# M55M1 register map
File version: 1.0
Registers are 32-bit, read-write, reset 0x0 unless marked. A register's access mark holds for its fields unless they carry their own. Offsets are from the block's base; [hi:lo] are bit positions; {n}, {i} and the like mark numbered series; 'fields as' and 'values as' point back to an identical list.

## SYS (part 3 of 3) — SYS Register Map
Base 0x40000000
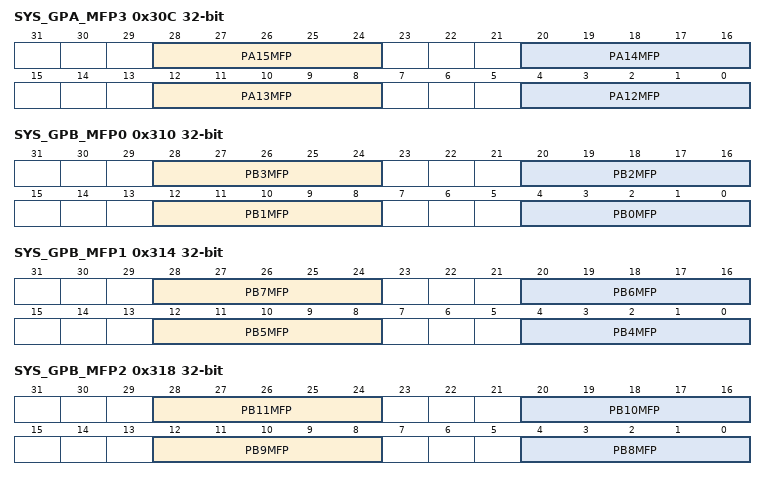
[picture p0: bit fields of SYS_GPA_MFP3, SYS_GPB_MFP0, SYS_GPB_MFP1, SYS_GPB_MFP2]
0x30C SYS_GPA_MFP3 — GPIOA Multiple Function Control Register 3
  [28:24] PA15MFP — PA.15 Multi-function Pin Selection. Note: These bits are not retained when D2 power is turned off.
  [20:16] PA14MFP — PA.14 Multi-function Pin Selection. Note: These bits are not retained when D2 power is turned off.
  [12:8] PA13MFP — PA.13 Multi-function Pin Selection. Note: These bits are not retained when D2 power is turned off.
  [4:0] PA12MFP — PA.12 Multi-function Pin Selection. Note: These bits are not retained when D2 power is turned off.
0x310 SYS_GPB_MFP0 — GPIOB Multiple Function Control Register 0
  [28:24] PB3MFP — PB.3 Multi-function Pin Selection. Note: These bits are not retained when D2 power is turned off.
  [20:16] PB2MFP — PB.2 Multi-function Pin Selection. Note: These bits are not retained when D2 power is turned off.
  [12:8] PB1MFP — PB.1 Multi-function Pin Selection. Note: These bits are not retained when D2 power is turned off.
  [4:0] PB0MFP — PB.0 Multi-function Pin Selection. Note: These bits are not retained when D2 power is turned off.
0x314 SYS_GPB_MFP1 — GPIOB Multiple Function Control Register 1
  [28:24] PB7MFP — PB.7 Multi-function Pin Selection. Note: These bits are not retained when D2 power is turned off.
  [20:16] PB6MFP — PB.6 Multi-function Pin Selection. Note: These bits are not retained when D2 power is turned off.
  [12:8] PB5MFP — PB.5 Multi-function Pin Selection. Note: These bits are not retained when D2 power is turned off.
  [4:0] PB4MFP — PB.4 Multi-function Pin Selection. Note: These bits are not retained when D2 power is turned off.
0x318 SYS_GPB_MFP2 — GPIOB Multiple Function Control Register 2
  [28:24] PB11MFP — PB.11 Multi-function Pin Selection. Note: These bits are not retained when D2 power is turned off.
  [20:16] PB10MFP — PB.10 Multi-function Pin Selection. Note: These bits are not retained when D2 power is turned off.
  [12:8] PB9MFP — PB.9 Multi-function Pin Selection. Note: These bits are not retained when D2 power is turned off.
  [4:0] PB8MFP — PB.8 Multi-function Pin Selection. Note: These bits are not retained when D2 power is turned off.
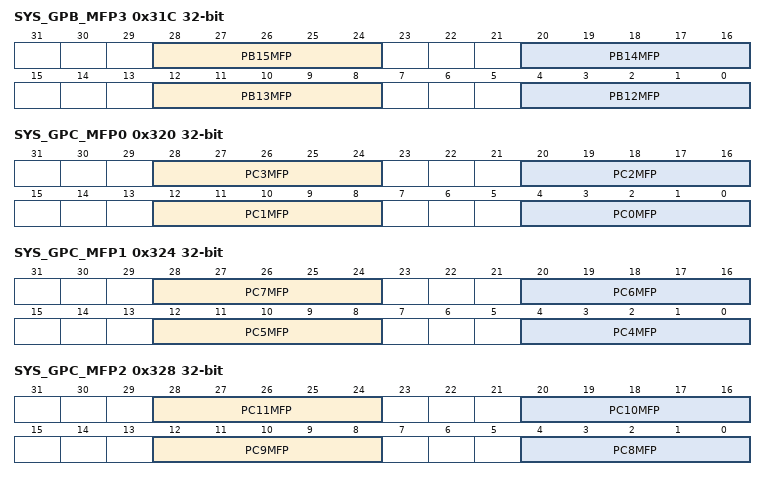
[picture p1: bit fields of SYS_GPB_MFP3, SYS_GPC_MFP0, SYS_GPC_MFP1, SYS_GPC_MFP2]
0x31C SYS_GPB_MFP3 — GPIOB Multiple Function Control Register 3
  [28:24] PB15MFP — PB.15 Multi-function Pin Selection. Note: These bits are not retained when D2 power is turned off.
  [20:16] PB14MFP — PB.14 Multi-function Pin Selection. Note: These bits are not retained when D2 power is turned off.
  [12:8] PB13MFP — PB.13 Multi-function Pin Selection. Note: These bits are not retained when D2 power is turned off.
  [4:0] PB12MFP — PB.12 Multi-function Pin Selection. Note: These bits are not retained when D2 power is turned off.
0x320 SYS_GPC_MFP0 — GPIOC Multiple Function Control Register 0
  [28:24] PC3MFP — PC.3 Multi-function Pin Selection. Note: These bits are not retained when D2 power is turned off.
  [20:16] PC2MFP — PC.2 Multi-function Pin Selection. Note: These bits are not retained when D2 power is turned off.
  [12:8] PC1MFP — PC.1 Multi-function Pin Selection. Note: These bits are not retained when D2 power is turned off.
  [4:0] PC0MFP — PC.0 Multi-function Pin Selection. Note: These bits are not retained when D2 power is turned off.
0x324 SYS_GPC_MFP1 — GPIOC Multiple Function Control Register 1
  [28:24] PC7MFP — PC.7 Multi-function Pin Selection. Note: These bits are not retained when D2 power is turned off.
  [20:16] PC6MFP — PC.6 Multi-function Pin Selection. Note: These bits are not retained when D2 power is turned off.
  [12:8] PC5MFP — PC.5 Multi-function Pin Selection. Note: These bits are not retained when D2 power is turned off.
  [4:0] PC4MFP — PC.4 Multi-function Pin Selection. Note: These bits are not retained when D2 power is turned off.
0x328 SYS_GPC_MFP2 — GPIOC Multiple Function Control Register 2
  [28:24] PC11MFP — PC.11 Multi-function Pin Selection. Note: These bits are not retained when D2 power is turned off.
  [20:16] PC10MFP — PC.10 Multi-function Pin Selection. Note: These bits are not retained when D2 power is turned off.
  [12:8] PC9MFP — PC.9 Multi-function Pin Selection. Note: These bits are not retained when D2 power is turned off.
  [4:0] PC8MFP — PC.8 Multi-function Pin Selection. Note: These bits are not retained when D2 power is turned off.
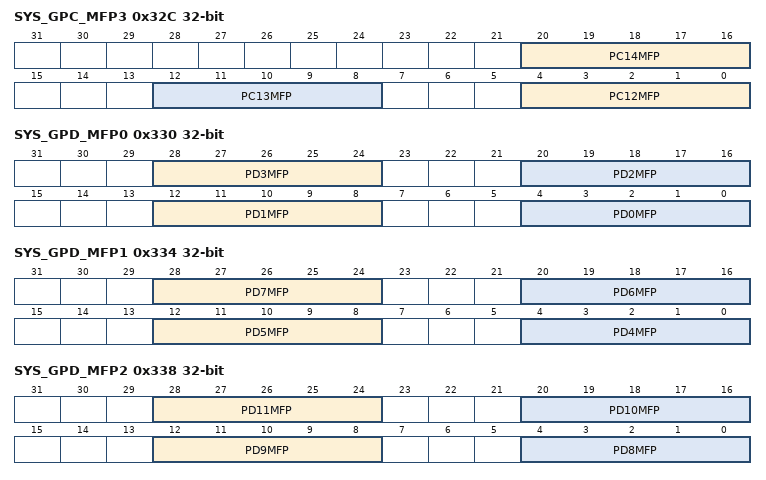
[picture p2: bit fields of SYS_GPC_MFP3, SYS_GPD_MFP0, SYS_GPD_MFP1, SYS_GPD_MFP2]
0x32C SYS_GPC_MFP3 — GPIOC Multiple Function Control Register 3
  [20:16] PC14MFP — PC.14 Multi-function Pin Selection. Note: These bits are not retained when D2 power is turned off.
  [12:8] PC13MFP — PC.13 Multi-function Pin Selection. Note: These bits are not retained when D2 power is turned off.
  [4:0] PC12MFP — PC.12 Multi-function Pin Selection. Note: These bits are not retained when D2 power is turned off.
0x330 SYS_GPD_MFP0 — GPIOD Multiple Function Control Register 0
  [28:24] PD3MFP — PD.3 Multi-function Pin Selection. Note: These bits are not retained when D2 power is turned off.
  [20:16] PD2MFP — PD.2 Multi-function Pin Selection. Note: These bits are not retained when D2 power is turned off.
  [12:8] PD1MFP — PD.1 Multi-function Pin Selection. Note: These bits are not retained when D2 power is turned off.
  [4:0] PD0MFP — PD.0 Multi-function Pin Selection. Note: These bits are not retained when D2 power is turned off.
0x334 SYS_GPD_MFP1 — GPIOD Multiple Function Control Register 1
  [28:24] PD7MFP — PD.7 Multi-function Pin Selection. Note: These bits are not retained when D2 power is turned off.
  [20:16] PD6MFP — PD.6 Multi-function Pin Selection. Note: These bits are not retained when D2 power is turned off.
  [12:8] PD5MFP — PD.5 Multi-function Pin Selection. Note: These bits are not retained when D2 power is turned off.
  [4:0] PD4MFP — PD.4 Multi-function Pin Selection. Note: These bits are not retained when D2 power is turned off.
0x338 SYS_GPD_MFP2 — GPIOD Multiple Function Control Register 2
  [28:24] PD11MFP — PD.11 Multi-function Pin Selection. Note: These bits are not retained when D2 power is turned off.
  [20:16] PD10MFP — PD.10 Multi-function Pin Selection. Note: These bits are not retained when D2 power is turned off.
  [12:8] PD9MFP — PD.9 Multi-function Pin Selection. Note: These bits are not retained when D2 power is turned off.
  [4:0] PD8MFP — PD.8 Multi-function Pin Selection. Note: These bits are not retained when D2 power is turned off.
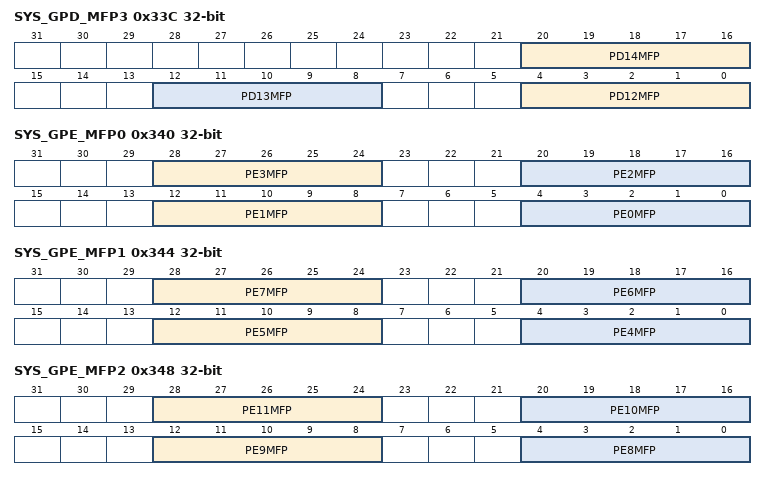
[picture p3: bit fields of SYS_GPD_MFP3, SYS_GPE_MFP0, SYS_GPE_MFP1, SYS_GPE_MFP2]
0x33C SYS_GPD_MFP3 — GPIOD Multiple Function Control Register 3
  [20:16] PD14MFP — PD.14 Multi-function Pin Selection. Note: These bits are not retained when D2 power is turned off.
  [12:8] PD13MFP — PD.13 Multi-function Pin Selection. Note: These bits are not retained when D2 power is turned off.
  [4:0] PD12MFP — PD.12 Multi-function Pin Selection. Note: These bits are not retained when D2 power is turned off.
0x340 SYS_GPE_MFP0 — GPIOE Multiple Function Control Register 0
  [28:24] PE3MFP — PE.3 Multi-function Pin Selection. Note: These bits are not retained when D2 power is turned off.
  [20:16] PE2MFP — PE.2 Multi-function Pin Selection. Note: These bits are not retained when D2 power is turned off.
  [12:8] PE1MFP — PE.1 Multi-function Pin Selection. Note: These bits are not retained when D2 power is turned off.
  [4:0] PE0MFP — PE.0 Multi-function Pin Selection. Note: These bits are not retained when D2 power is turned off.
0x344 SYS_GPE_MFP1 — GPIOE Multiple Function Control Register 1
  [28:24] PE7MFP — PE.7 Multi-function Pin Selection. Note: These bits are not retained when D2 power is turned off.
  [20:16] PE6MFP — PE.6 Multi-function Pin Selection. Note: These bits are not retained when D2 power is turned off.
  [12:8] PE5MFP — PE.5 Multi-function Pin Selection. Note: These bits are not retained when D2 power is turned off.
  [4:0] PE4MFP — PE.4 Multi-function Pin Selection. Note: These bits are not retained when D2 power is turned off.
0x348 SYS_GPE_MFP2 — GPIOE Multiple Function Control Register 2
  [28:24] PE11MFP — PE.11 Multi-function Pin Selection. Note: These bits are not retained when D2 power is turned off.
  [20:16] PE10MFP — PE.10 Multi-function Pin Selection. Note: These bits are not retained when D2 power is turned off.
  [12:8] PE9MFP — PE.9 Multi-function Pin Selection. Note: These bits are not retained when D2 power is turned off.
  [4:0] PE8MFP — PE.8 Multi-function Pin Selection. Note: These bits are not retained when D2 power is turned off.
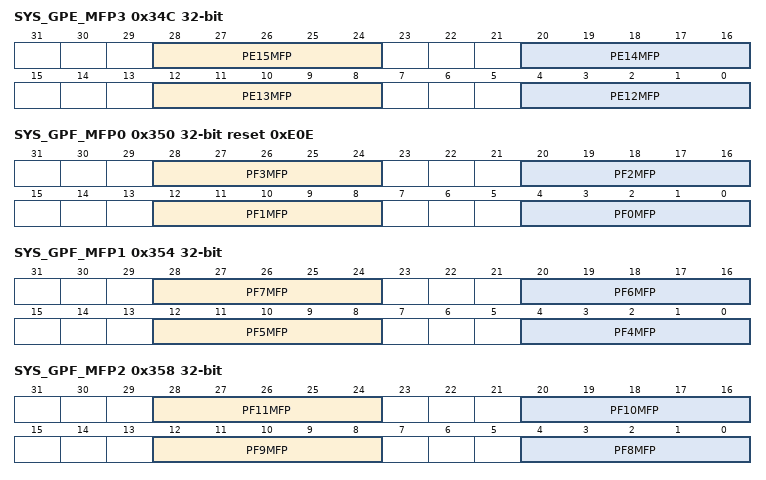
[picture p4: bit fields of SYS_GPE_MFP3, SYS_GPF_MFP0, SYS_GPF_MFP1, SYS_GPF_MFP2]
0x34C SYS_GPE_MFP3 — GPIOE Multiple Function Control Register 3
  [28:24] PE15MFP — PE.15 Multi-function Pin Selection. Note: These bits are not retained when D2 power is turned off.
  [20:16] PE14MFP — PE.14 Multi-function Pin Selection. Note: These bits are not retained when D2 power is turned off.
  [12:8] PE13MFP — PE.13 Multi-function Pin Selection. Note: These bits are not retained when D2 power is turned off.
  [4:0] PE12MFP — PE.12 Multi-function Pin Selection. Note: These bits are not retained when D2 power is turned off.
0x350 SYS_GPF_MFP0 reset 0xE0E — GPIOF Multiple Function Control Register 0
  [28:24] PF3MFP — PF.3 Multi-function Pin Selection. Note: These bits are not retained when D2 power is turned off.
  [20:16] PF2MFP — PF.2 Multi-function Pin Selection. Note: These bits are not retained when D2 power is turned off.
  [12:8] PF1MFP — PF.1 Multi-function Pin Selection. Note: These bits are not retained when D2 power is turned off.
  [4:0] PF0MFP — PF.0 Multi-function Pin Selection. Note: These bits are not retained when D2 power is turned off.
0x354 SYS_GPF_MFP1 — GPIOF Multiple Function Control Register 1
  [28:24] PF7MFP — PF.7 Multi-function Pin Selection. Note: These bits are not retained when D2 power is turned off.
  [20:16] PF6MFP — PF.6 Multi-function Pin Selection. Note: These bits are not retained when D2 power is turned off.
  [12:8] PF5MFP — PF.5 Multi-function Pin Selection. Note: These bits are not retained when D2 power is turned off.
  [4:0] PF4MFP — PF.4 Multi-function Pin Selection. Note: These bits are not retained when D2 power is turned off.
0x358 SYS_GPF_MFP2 — GPIOF Multiple Function Control Register 2
  [28:24] PF11MFP — PF.11 Multi-function Pin Selection. Note: These bits are not retained when D2 power is turned off.
  [20:16] PF10MFP — PF.10 Multi-function Pin Selection. Note: These bits are not retained when D2 power is turned off.
  [12:8] PF9MFP — PF.9 Multi-function Pin Selection. Note: These bits are not retained when D2 power is turned off.
  [4:0] PF8MFP — PF.8 Multi-function Pin Selection. Note: These bits are not retained when D2 power is turned off.
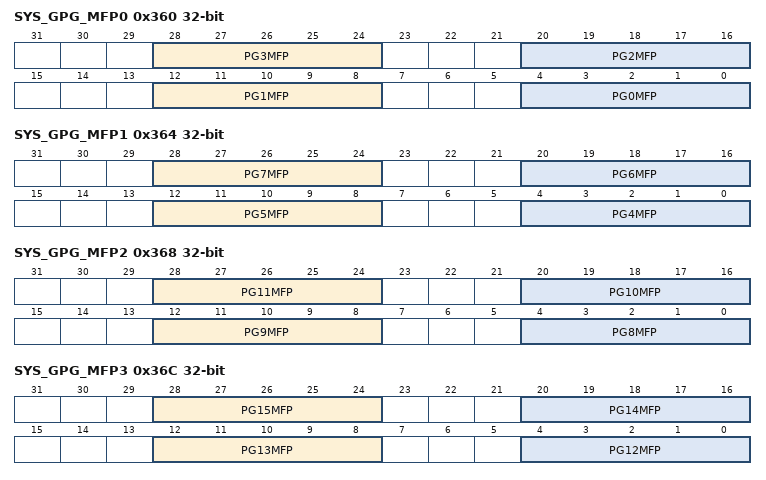
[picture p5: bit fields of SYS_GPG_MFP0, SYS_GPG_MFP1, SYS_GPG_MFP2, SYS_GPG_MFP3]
0x360 SYS_GPG_MFP0 — GPIOG Multiple Function Control Register 0
  [28:24] PG3MFP — PG.3 Multi-function Pin Selection. Note: These bits are not retained when D2 power is turned off.
  [20:16] PG2MFP — PG.2 Multi-function Pin Selection. Note: These bits are not retained when D2 power is turned off.
  [12:8] PG1MFP — PG.1 Multi-function Pin Selection. Note: These bits are not retained when D2 power is turned off.
  [4:0] PG0MFP — PG.0 Multi-function Pin Selection. Note: These bits are not retained when D2 power is turned off.
0x364 SYS_GPG_MFP1 — GPIOG Multiple Function Control Register 1
  [28:24] PG7MFP — PG.7 Multi-function Pin Selection. Note: These bits are not retained when D2 power is turned off.
  [20:16] PG6MFP — PG.6 Multi-function Pin Selection. Note: These bits are not retained when D2 power is turned off.
  [12:8] PG5MFP — PG.5 Multi-function Pin Selection. Note: These bits are not retained when D2 power is turned off.
  [4:0] PG4MFP — PG.4 Multi-function Pin Selection. Note: These bits are not retained when D2 power is turned off.
0x368 SYS_GPG_MFP2 — GPIOG Multiple Function Control Register 2
  [28:24] PG11MFP — PG.11 Multi-function Pin Selection. Note: These bits are not retained when D2 power is turned off.
  [20:16] PG10MFP — PG.10 Multi-function Pin Selection. Note: These bits are not retained when D2 power is turned off.
  [12:8] PG9MFP — PG.9 Multi-function Pin Selection. Note: These bits are not retained when D2 power is turned off.
  [4:0] PG8MFP — PG.8 Multi-function Pin Selection. Note: These bits are not retained when D2 power is turned off.
0x36C SYS_GPG_MFP3 — GPIOG Multiple Function Control Register 3
  [28:24] PG15MFP — PG.15 Multi-function Pin Selection. Note: These bits are not retained when D2 power is turned off.
  [20:16] PG14MFP — PG.14 Multi-function Pin Selection. Note: These bits are not retained when D2 power is turned off.
  [12:8] PG13MFP — PG.13 Multi-function Pin Selection. Note: These bits are not retained when D2 power is turned off.
  [4:0] PG12MFP — PG.12 Multi-function Pin Selection. Note: These bits are not retained when D2 power is turned off.
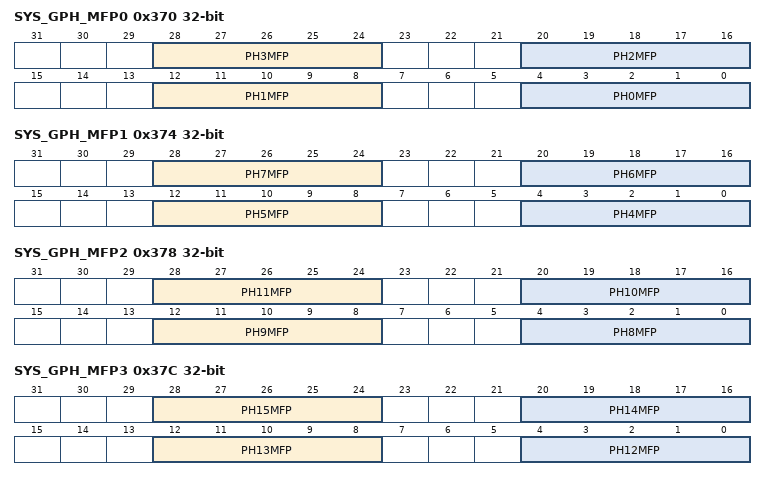
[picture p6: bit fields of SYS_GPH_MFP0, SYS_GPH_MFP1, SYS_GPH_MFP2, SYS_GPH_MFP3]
0x370 SYS_GPH_MFP0 — GPIOH Multiple Function Control Register 0
  [28:24] PH3MFP — PH.3 Multi-function Pin Selection. Note: These bits are not retained when D2 power is turned off.
  [20:16] PH2MFP — PH.2 Multi-function Pin Selection. Note: These bits are not retained when D2 power is turned off.
  [12:8] PH1MFP — PH.1 Multi-function Pin Selection. Note: These bits are not retained when D2 power is turned off.
  [4:0] PH0MFP — PH.0 Multi-function Pin Selection. Note: These bits are not retained when D2 power is turned off.
0x374 SYS_GPH_MFP1 — GPIOH Multiple Function Control Register 1
  [28:24] PH7MFP — PH.7 Multi-function Pin Selection. Note: These bits are not retained when D2 power is turned off.
  [20:16] PH6MFP — PH.6 Multi-function Pin Selection. Note: These bits are not retained when D2 power is turned off.
  [12:8] PH5MFP — PH.5 Multi-function Pin Selection. Note: These bits are not retained when D2 power is turned off.
  [4:0] PH4MFP — PH.4 Multi-function Pin Selection. Note: These bits are not retained when D2 power is turned off.
0x378 SYS_GPH_MFP2 — GPIOH Multiple Function Control Register 2
  [28:24] PH11MFP — PH.11 Multi-function Pin Selection. Note: These bits are not retained when D2 power is turned off.
  [20:16] PH10MFP — PH.10 Multi-function Pin Selection. Note: These bits are not retained when D2 power is turned off.
  [12:8] PH9MFP — PH.9 Multi-function Pin Selection. Note: These bits are not retained when D2 power is turned off.
  [4:0] PH8MFP — PH.8 Multi-function Pin Selection. Note: These bits are not retained when D2 power is turned off.
0x37C SYS_GPH_MFP3 — GPIOH Multiple Function Control Register 3
  [28:24] PH15MFP — PH.15 Multi-function Pin Selection. Note: These bits are not retained when D2 power is turned off.
  [20:16] PH14MFP — PH.14 Multi-function Pin Selection. Note: These bits are not retained when D2 power is turned off.
  [12:8] PH13MFP — PH.13 Multi-function Pin Selection. Note: These bits are not retained when D2 power is turned off.
  [4:0] PH12MFP — PH.12 Multi-function Pin Selection. Note: These bits are not retained when D2 power is turned off.
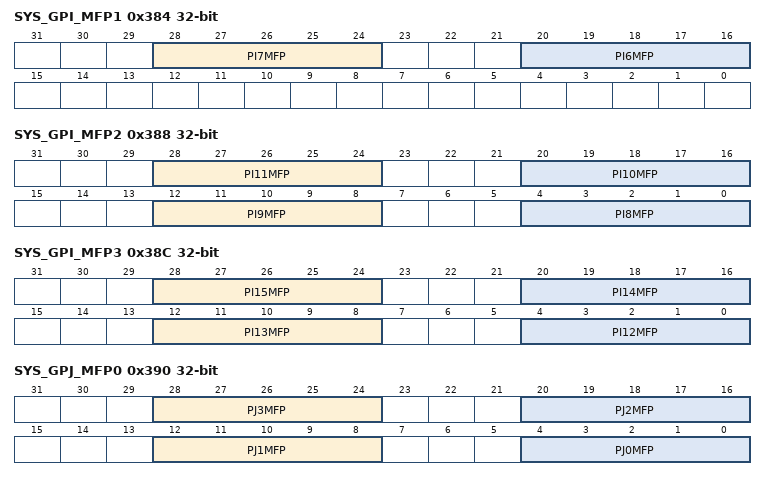
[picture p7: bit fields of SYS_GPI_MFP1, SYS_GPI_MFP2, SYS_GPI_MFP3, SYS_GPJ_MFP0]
0x384 SYS_GPI_MFP1 — GPIOI Multiple Function Control Register 1
  [28:24] PI7MFP — PI.7 Multi-function Pin Selection. Note: These bits are not retained when D2 power is turned off.
  [20:16] PI6MFP — PI.6 Multi-function Pin Selection. Note: These bits are not retained when D2 power is turned off.
0x388 SYS_GPI_MFP2 — GPIOI Multiple Function Control Register 2
  [28:24] PI11MFP — PI.11 Multi-function Pin Selection. Note: These bits are not retained when D2 power is turned off.
  [20:16] PI10MFP — PI.10 Multi-function Pin Selection. Note: These bits are not retained when D2 power is turned off.
  [12:8] PI9MFP — PI.9 Multi-function Pin Selection. Note: These bits are not retained when D2 power is turned off.
  [4:0] PI8MFP — PI.8 Multi-function Pin Selection. Note: These bits are not retained when D2 power is turned off.
0x38C SYS_GPI_MFP3 — GPIOI Multiple Function Control Register 3
  [28:24] PI15MFP — PI.15 Multi-function Pin Selection. Note: These bits are not retained when D2 power is turned off.
  [20:16] PI14MFP — PI.14 Multi-function Pin Selection. Note: These bits are not retained when D2 power is turned off.
  [12:8] PI13MFP — PI.13 Multi-function Pin Selection. Note: These bits are not retained when D2 power is turned off.
  [4:0] PI12MFP — PI.12 Multi-function Pin Selection. Note: These bits are not retained when D2 power is turned off.
0x390 SYS_GPJ_MFP0 — GPIOJ Multiple Function Control Register 0
  [28:24] PJ3MFP — PJ.3 Multi-function Pin Selection. Note: These bits are not retained when D2 power is turned off.
  [20:16] PJ2MFP — PJ.2 Multi-function Pin Selection. Note: These bits are not retained when D2 power is turned off.
  [12:8] PJ1MFP — PJ.1 Multi-function Pin Selection. Note: These bits are not retained when D2 power is turned off.
  [4:0] PJ0MFP — PJ.0 Multi-function Pin Selection. Note: These bits are not retained when D2 power is turned off.
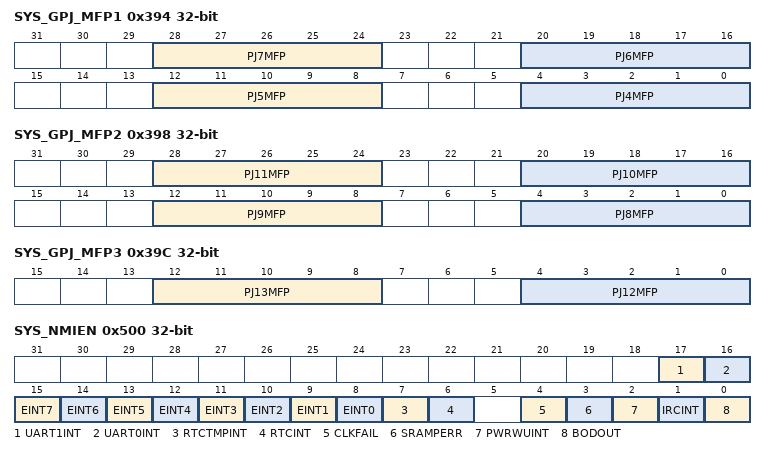
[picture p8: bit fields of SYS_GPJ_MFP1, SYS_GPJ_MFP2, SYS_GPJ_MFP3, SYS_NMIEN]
0x394 SYS_GPJ_MFP1 — GPIOJ Multiple Function Control Register 1
  [28:24] PJ7MFP — PJ.7 Multi-function Pin Selection. Note: These bits are not retained when D2 power is turned off.
  [20:16] PJ6MFP — PJ.6 Multi-function Pin Selection. Note: These bits are not retained when D2 power is turned off.
  [12:8] PJ5MFP — PJ.5 Multi-function Pin Selection. Note: These bits are not retained when D2 power is turned off.
  [4:0] PJ4MFP — PJ.4 Multi-function Pin Selection. Note: These bits are not retained when D2 power is turned off.
0x398 SYS_GPJ_MFP2 — GPIOJ Multiple Function Control Register 2
  [28:24] PJ11MFP — PJ.11 Multi-function Pin Selection. Note: These bits are not retained when D2 power is turned off.
  [20:16] PJ10MFP — PJ.10 Multi-function Pin Selection. Note: These bits are not retained when D2 power is turned off.
  [12:8] PJ9MFP — PJ.9 Multi-function Pin Selection. Note: These bits are not retained when D2 power is turned off.
  [4:0] PJ8MFP — PJ.8 Multi-function Pin Selection. Note: These bits are not retained when D2 power is turned off.
0x39C SYS_GPJ_MFP3 — GPIOJ Multiple Function Control Register 3
  [12:8] PJ13MFP — PJ.13 Multi-function Pin Selection. Note: These bits are not retained when D2 power is turned off.
  [4:0] PJ12MFP — PJ.12 Multi-function Pin Selection. Note: These bits are not retained when D2 power is turned off.
0x500 SYS_NMIEN — NMI Source Interrupt Enable Register
  [17] UART1INT — UART1 NMI Source Enable (Write Protect). Note 1: This bit is write protected. Refer to the SYS_REGLCTL register. Note 2: This bit is not retained when D1 power is turned off.
    0=UART1 NMI source Disabled; 1=UART1 NMI source Enabled
  [16] UART0INT — UART0 NMI Source Enable (Write Protect). Note 1: This bit is write protected. Refer to the SYS_REGLCTL register. Note 2: This bit is not retained when D1 power is turned off.
    0=UART0 NMI source Disabled; 1=UART0 NMI source Enabled
  [15] EINT7 — External Interrupt From PB.9 or PD.10 Pin NMI Source Enable (Write Protect). Note 1: This bit is write protected. Refer to the SYS_REGLCTL register. Note 2: This bit is not retained when D1 power is turned off.
    0=External interrupt from PB.9 or PD.10 pin NMI source Disabled; 1=External interrupt from PB.9 or PD.10 pin NMI source Enabled
  [14] EINT6 — External Interrupt From PB.8 or PD.11 Pin NMI Source Enable (Write Protect). Note 1: This bit is write protected. Refer to the SYS_REGLCTL register. Note 2: This bit is not retained when D1 power is turned off.
    0=External interrupt from PB.8 or PD.11 pin NMI source Disabled; 1=External interrupt from PB.8 or PD.11 pin NMI source Enabled
  [13] EINT5 — External Interrupt From PB.7 or PD.12 Pin NMI Source Enable (Write Protect). Note 1: This bit is write protected. Refer to the SYS_REGLCTL register. Note 2: This bit is not retained when D1 power is turned off.
    0=External interrupt from PB.7 or PD.12 pin NMI source Disabled; 1=External interrupt from PB.7 or PD.12 pin NMI source Enabled
  [12] EINT4 — External Interrupt From PA.8 or PB.6 Pin NMI Source Enable (Write Protect). Note 1: This bit is write protected. Refer to the SYS_REGLCTL register. Note 2: This bit is not retained when D1 power is turned off.
    0=External interrupt from PA.8 or PB.6 pin NMI source Disabled; 1=External interrupt from PA.8 or PB.6 pin NMI source Enabled
  [11] EINT3 — External Interrupt From PB.2 or PC.7 Pin NMI Source Enable (Write Protect). Note 1: This bit is write protected. Refer to the SYS_REGLCTL register. Note 2: This bit is not retained when D1 power is turned off.
    0=External interrupt from PB.2 or PC.7pin NMI source Disabled; 1=External interrupt from PB.2 or PC.7 pin NMI source Enabled
  [10] EINT2 — External Interrupt From PB.3 or PC.6 Pin NMI Source Enable (Write Protect). Note 1: This bit is write protected. Refer to the SYS_REGLCTL register. Note 2: This bit is not retained when D1 power is turned off.
    0=External interrupt from PB.3 or PC.6 pin NMI source Disabled; 1=External interrupt from PB.3 or PC.6 pin NMI source Enabled
  [9] EINT1 — External Interrupt From PA.7 or PB.4 Pin NMI Source Enable (Write Protect). Note 1: This bit is write protected. Refer to the SYS_REGLCTL register. Note 2: This bit is not retained when D1 power is turned off.
    0=External interrupt from PA.7 or PB.4 pin NMI source Disabled; 1=External interrupt from PA.7 or P4.4 pin NMI source Enabled
  [8] EINT0 — External Interrupt From PA.6, or PB.5 Pin NMI Source Enable (Write Protect). Note 1: This bit is write protected. Refer to the SYS_REGLCTL register. Note 2: This bit is not retained when D1 power is turned off.
    0=External interrupt from PA.6, or PB.5 pin NMI source Disabled; 1=External interrupt from PA.6, or PB.5 pin NMI source Enabled
  [7] RTCTMPINT — RTC Tamper Interrupt NMI Source Enable (Write Protect). Note 1: This bit is write protected. Refer to the SYS_REGLCTL register. Note 2: This bit is not retained when D1 power is turned off.
    0=Backup register tamper detected interrupt NMI source Disabled; 1=Backup register tamper detected interrupt NMI source Enabled
  [6] RTCINT — RTC NMI Source Enable (Write Protect). Note 1: This bit is write protected. Refer to the SYS_REGLCTL register. Note 2: This bit is not retained when D1 power is turned off.
    0=RTC NMI source Disabled; 1=RTC NMI source Enabled
  [4] CLKFAIL — Clock Fail Detected NMI Source Enable (Write Protect). Note 1: This bit is write protected. Refer to the SYS_REGLCTL register. Note 2: This bit is not retained when D1 power is turned off.
    0=Clock fail detected interrupt NMI source Disabled; 1=Clock fail detected interrupt NMI source Enabled
  [3] SRAMPERR — SRAM Parity Check Error NMI Source Enable (Write Protect). Note 1: This bit is write protected. Refer to the SYS_REGLCTL register. Note 2: This bit is not retained when D1 power is turned off.
    0=SRAM parity check error NMI source Disabled; 1=SRAM parity check error NMI source Enabled
  [2] PWRWUINT — Power-down Mode Wake-up NMI Source Enable (Write Protect). Note 1: This bit is write protected. Refer to the SYS_REGLCTL register. Note 2: This bit is not retained when D1 power is turned off.
    0=Power-down mode wake-up NMI source Disabled; 1=Power-down mode wake-up NMI source Enabled
  [1] IRCINT — IRC TRIM NMI Source Enable (Write Protect). Note 1: This bit is write protected. Refer to the SYS_REGLCTL register. Note 2: This bit is not retained when D0 power is turned off.
    0=IRC TRIM NMI source Disabled; 1=IRC TRIM NMI source Enabled
  [0] BODOUT — BOD NMI Source Enable (Write Protect). Note 1: This bit is write protected. Refer to the SYS_REGLCTL register. Note 2: This bit is not retained when D1 power is turned off.
    0=BOD NMI source Disabled; 1=BOD NMI source Enabled
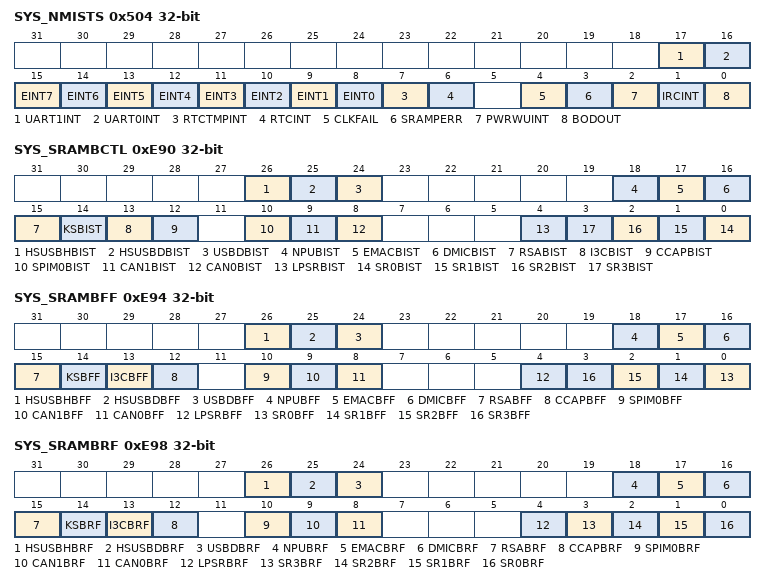
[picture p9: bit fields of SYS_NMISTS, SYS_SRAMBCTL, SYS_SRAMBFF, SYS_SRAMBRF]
0x504 SYS_NMISTS ro — NMI Source Interrupt Status Register
  [17] UART1INT — UART1 Interrupt Flag (Read Only)
    0=UART1 interrupt is deasserted; 1=UART1 interrupt is asserted
  [16] UART0INT — UART0 Interrupt Flag (Read Only)
    values as UART1INT
  [15] EINT7 — External Interrupt From PB.9 or PD.10 Pin Interrupt Flag (Read Only)
    0=External Interrupt from PB.9 or PD.10 interrupt is deasserted; 1=External Interrupt from PB.9 or PD.10 interrupt is asserted
  [14] EINT6 — External Interrupt From PB.8 or PD.11 Pin Interrupt Flag (Read Only)
    0=External Interrupt from PB.8 or PD.11 interrupt is deasserted; 1=External Interrupt from PB.8 or PD.11 interrupt is asserted
  [13] EINT5 — External Interrupt From PB.7 or PD.12 Pin Interrupt Flag (Read Only)
    0=External Interrupt from PB.7 or PD.12 interrupt is deasserted; 1=External Interrupt from PB.7 or PD.12 interrupt is asserted
  [12] EINT4 — External Interrupt From PA.8 or PB.6 Pin Interrupt Flag (Read Only)
    0=External Interrupt from PA.8 or PB.6 interrupt is deasserted; 1=External Interrupt from PA.8 or PB.6 interrupt is asserted
  [11] EINT3 — External Interrupt From PB.2 or PC.7 Pin Interrupt Flag (Read Only)
    0=External Interrupt from PB.2 or PC.7 interrupt is deasserted; 1=External Interrupt from PB.2 or PC.7 interrupt is asserted
  [10] EINT2 — External Interrupt From PB.3 or PC.6 Pin Interrupt Flag (Read Only)
    0=External Interrupt from PB.3 or PC.6 interrupt is deasserted; 1=External Interrupt from PB.3 or PC.6 interrupt is asserted
  [9] EINT1 — External Interrupt From PA.7, or PB.4 Pin Interrupt Flag (Read Only)
    0=External Interrupt from PA.7, or PB.4 interrupt is deasserted; 1=External Interrupt from PA.7, or PB.4 interrupt is asserted
  [8] EINT0 — External Interrupt From PA.6, or PB.5 Pin Interrupt Flag (Read Only)
    0=External Interrupt from PA.6, or PB.5 interrupt is deasserted; 1=External Interrupt from PA.6, or PB.5 interrupt is asserted
  [7] RTCTMPINT — RTC Tamper Interrupt Flag (Read Only)
    0=Backup register tamper detected interrupt is deasserted; 1=Backup register tamper detected interrupt is asserted
  [6] RTCINT — RTC Interrupt Flag (Read Only)
    0=RTC interrupt is deasserted; 1=RTC interrupt is asserted
  [4] CLKFAIL — Clock Fail Detected Interrupt Flag (Read Only)
    0=Clock fail detected interrupt is deasserted; 1=Clock fail detected interrupt is asserted
  [3] SRAMPERR — SRAM Parity Check Error Interrupt Flag (Read Only)
    0=SRAM parity check error interrupt is deasserted; 1=SRAM parity check error interrupt is asserted
  [2] PWRWUINT — Power-down Mode Wake-up Interrupt Flag (Read Only)
    0=Power-down mode wake-up interrupt is deasserted; 1=Power-down mode wake-up interrupt is asserted
  [1] IRCINT — IRC TRIM Interrupt Flag (Read Only)
    0=HIRC TRIM interrupt is deasserted; 1=HIRC TRIM interrupt is asserted
  [0] BODOUT — BOD Interrupt Flag (Read Only)
    0=BOD interrupt is deasserted; 1=BOD interrupt is asserted
0xE90 SYS_SRAMBCTL — System SRAM BIST Control Register
  [26] HSUSBHBIST — HSUSBH SRAM BIST Enable Bit (Write Protect). This bit enables HSUSBH SRAM BIST function. Note: This bit is write protected. Refer to the SYS_REGLCTL register.
    0=HSUSBH SRAM BIST Disabled; 1=HSUSBH SRAM BIST Enabled
  [25] HSUSBDBIST — HSUSBD SRAM BIST Enable Bit (Write Protect). This bit enables HSUSBD SRAM BIST function. Note: This bit is write protected. Refer to the SYS_REGLCTL register.
    0=HSUSBD SRAM BIST Disabled; 1=HSUSBD SRAM BIST Enabled
  [24] USBDBIST — USBD SRAM BIST Enable Bit (Write Protect). This bit enables USBD SRAM BIST function. Note: This bit is write protected. Refer to the SYS_REGLCTL register.
    0=USBD SRAM BIST Disabled; 1=USBD SRAM BIST Enabled
  [18] NPUBIST — NPU SRAM BIST Enable Bit (Write Protect). This bit enables NPU SRAM BIST function. Note: This bit is write protected. Refer to the SYS_REGLCTL register.
    0=NPU SRAM BIST Disabled; 1=NPU SRAM BIST Enabled
  [17] EMACBIST — EMAC SRAM BIST Enable Bit (Write Protect). This bit enables EMAC SRAM BIST function. Note: This bit is write protected. Refer to the SYS_REGLCTL register.
    0=EMAC SRAM BIST Disabled; 1=EMAC SRAM BIST Enabled
  [16] DMICBIST — DMIC SRAM BIST Enable Bit (Write Protect). This bit enables DMIC SRAM BIST function. Note: This bit is write protected. Refer to the SYS_REGLCTL register.
    0=DMIC SRAM BIST Disabled; 1=DMIC SRAM BIST Enabled
  [15] RSABIST — RSA SRAM BIST Enable Bit (Write Protect). This bit enables RSA SRAM BIST function. Note: This bit is write protected. Refer to the SYS_REGLCTL register.
    0=RSA SRAM BIST Disabled; 1=RSA SRAM BIST Enabled
  [14] KSBIST — KS SRAM BIST Enable Bit (Write Protect). This bit enables KS SRAM BIST function. Note: This bit is write protected. Refer to the SYS_REGLCTL register.
    0=KS SRAM BIST Disabled; 1=KS SRAM BIST Enabled
  [13] I3CBIST — I3C SRAM BIST Enable Bit (Write Protect). This bit enables I3C SRAM BIST function. Note: This bit is write protected. Refer to the SYS_REGLCTL register.
    0=I3C SRAM BIST Disabled; 1=I3C SRAM BIST Enabled
  [12] CCAPBIST — CCAP SRAM BIST Enable Bit (Write Protect). This bit enables CCAP SRAM BIST function. Note: This bit is write protected. Refer to the SYS_REGLCTL register.
    0=CCAP SRAM BIST Disabled; 1=CCAP SRAM BIST Enabled
  [10] SPIM0BIST — SPIM0 SRAM BIST Enable Bit (Write Protect). This bit enables SPIM0 SRAM BIST function. Note: This bit is write protected. Refer to the SYS_REGLCTL register.
    0=SPIM0 SRAM BIST Disabled; 1=SPIM0 SRAM BIST Enabled
  [9] CAN1BIST — CAN1 SRAM BIST Enable Bit (Write Protect). This bit enables CAN1 SRAM BIST function. Note: This bit is write protected. Refer to the SYS_REGLCTL register.
    0=CAN1 SRAM BIST Disabled; 1=CAN1 SRAM BIST Enabled
  [8] CAN0BIST — CAN0 SRAM BIST Enable Bit (Write Protect). This bit enables CAN0 SRAM BIST function. Note: This bit is write protected. Refer to the SYS_REGLCTL register.
    0=CAN0 SRAM BIST Disabled; 1=CAN0 SRAM BIST Enabled
  [4] LPSRBIST — Low Power System SRAM BIST Enable Bit (Write Protect). This bit enables Low Power System SRAM BIST function. Note: This bit is write protected. Refer to the SYS_REGLCTL register.
    0=Low Power System SRAM BIST Disabled; 1=Low Power System SRAM BIST Enabled
  [n] SR{n}BIST (n=0..3) — System SRAM {n} BIST Enable Bit (Write Protect). This bit enables System SRAM {n} BIST function. Note: This bit is write protected. Refer to the SYS_REGLCTL register.
    0=System SRAM {n} BIST Disabled; 1=System SRAM {n} BIST Enabled
0xE94 SYS_SRAMBFF ro — System SRAM BIST Finish Flag Register
  [26] HSUSBHBFF — HSUSBH SRAM BIST Finish Flag (Read Only). Note 1: This bit will be clear to 0 when HSUSBHBIST(SYS_SRAMBCTL[26]) set to 0.
    0=HSUSBH SRAM BIST is active; 1=HSUSBH SRAM BIST test finish
  [25] HSUSBDBFF — HSUSBD SRAM BIST Finish Flag (Read Only). Note 1: This bit will be clear to 0 when HSUSBDBIST(SYS_SRAMBCTL[25]) set to 0.
    0=HSUSBD SRAM BIST is active; 1=HSUSBD SRAM BIST test finish
  [24] USBDBFF — USBD SRAM BIST Finish Flag (Read Only). Note 1: This bit will be clear to 0 when USBDBIST(SYS_SRAMBCTL[24]) set to 0.
    0=USBD SRAM BIST is active; 1=USBD SRAM BIST test finish
  [18] NPUBFF — NPU SRAM BIST Finish Flag (Read Only). Note 1: This bit will be clear to 0 when NPUBIST(SYS_SRAMBCTL[18]) set to 0.
    0=NPU SRAM BIST is active; 1=NPU SRAM BIST test finish
  [17] EMACBFF — EMAC SRAM BIST Finish Flag (Read Only). Note 1: This bit will be clear to 0 when EMACBIST(SYS_SRAMBCTL[17]) set to 0.
    0=EMAC SRAM BIST is active; 1=EMAC SRAM BIST test finish
  [16] DMICBFF — DMIC SRAM BIST Finish Flag (Read Only). Note 1: This bit will be clear to 0 when DMICBIST(SYS_SRAMBCTL[16]) set to 0.
    0=DMIC SRAM BIST is active; 1=DMIC SRAM BIST test finish
  [15] RSABFF — RSA SRAM BIST Finish Flag (Read Only). Note 1: This bit will be clear to 0 when RSABIST(SYS_SRAMBCTL[15]) set to 0.
    0=RSA SRAM BIST is active; 1=RSA SRAM BIST test finish
  [14] KSBFF — KS SRAM BIST Finish Flag (Read Only). Note 1: This bit will be clear to 0 when KSBIST(SYS_SRAMBCTL[14]) set to 0.
    0=KS SRAM BIST is active; 1=KS SRAM BIST test finish
  [13] I3CBFF — I3C SRAM BIST Finish Flag (Read Only). Note 1: This bit will be clear to 0 when I3CBIST(SYS_SRAMBCTL[13]) set to 0.
    0=I3C SRAM BIST is active; 1=I3C SRAM BIST test finish
  [12] CCAPBFF — CCAP SRAM BIST Finish Flag (Read Only). Note 1: This bit will be clear to 0 when CCAPBIST(SYS_SRAMBCTL[12]) set to 0.
    0=CCAP SRAM BIST is active; 1=CCAP SRAM BIST test finish
  [10] SPIM0BFF — SPIM0 SRAM BIST Finish Flag (Read Only). Note 1: This bit will be clear to 0 when SPIM0BIST(SYS_SRAMBCTL[10]) set to 0.
    0=SPIM0 SRAM BIST is active; 1=SPIM0 SRAM BIST test finish
  [9] CAN1BFF — CAN1 SRAM BIST Finish Flag (Read Only). Note 1: This bit will be clear to 0 when CAN1BIST(SYS_SRAMBCTL[9]) set to 0.
    0=CAN1 SRAM BIST is active; 1=CAN1 SRAM BIST test finish
  [8] CAN0BFF — CAN0 SRAM BIST Finish Flag (Read Only). Note 1: This bit will be clear to 0 when CAN0BIST(SYS_SRAMBCTL[8]) set to 0.
    0=CAN0 SRAM BIST is active; 1=CAN0 SRAM BIST test finish
  [4] LPSRBFF — Low Power System SRAM BIST Finish Flag (Read Only). Note 1: This bit will be clear to 0 when LPSRBIST(SYS_SRAMBCTL[4]) set to 0.
    0=Low Power System SRAM BIST is active; 1=Low Power System SRAM BIST test finish
  [n] SR{n}BFF (n=0..3) — System SRAM {n} BIST Finish Flag (Read Only). Note 1: This bit will be clear to 0 when SR{n}BIST(SYS_SRAMBCTL[{n}]) set to 0.
    0=System SRAM {n} BIST is active; 1=System SRAM {n} BIST test finish
0xE98 SYS_SRAMBRF ro — System SRAM BIST Result Flag Register
  [26] HSUSBHBRF — HSUSBH SRAM BIST Result Flag (Read Only). Note 1: This bit will be clear to 0 when HSUSBHBIST(SYS_SRAMBCTL[26]) set to 0.
    0=HSUSBH SRAM BIST test pass; 1=HSUSBH SRAM BIST test fail
  [25] HSUSBDBRF — HSUSBD SRAM BIST Result Flag (Read Only). Note 1: This bit will be clear to 0 when HSUSBDBIST(SYS_SRAMBCTL[25]) set to 0.
    0=HSUSBD SRAM BIST test pass; 1=HSUSBD SRAM BIST test fail
  [24] USBDBRF — USBD SRAM BIST Result Flag (Read Only). Note 1: This bit will be clear to 0 when USBDBIST(SYS_SRAMBCTL[24]) set to 0.
    0=USBD SRAM BIST test pass; 1=USBD SRAM BIST test fail
  [18] NPUBRF — NPU SRAM BIST Result Flag (Read Only). Note 1: This bit will be clear to 0 when NPUBIST(SYS_SRAMBCTL[18]) set to 0.
    0=NPU SRAM BIST test pass; 1=NPU SRAM BIST test fail
  [17] EMACBRF — EMAC SRAM BIST Result Flag (Read Only). Note 1: This bit will be clear to 0 when EMACBIST(SYS_SRAMBCTL[17]) set to 0.
    0=EMAC SRAM BIST test pass; 1=EMAC SRAM BIST test fail
  [16] DMICBRF — DMIC SRAM BIST Result Flag (Read Only). Note 1: This bit will be clear to 0 when DMICBIST(SYS_SRAMBCTL[16]) set to 0.
    0=DMIC SRAM BIST test pass; 1=DMIC SRAM BIST test fail
  [15] RSABRF — RSA SRAM BIST Result Flag (Read Only). Note 1: This bit will be clear to 0 when RSABIST(SYS_SRAMBCTL[15]) set to 0.
    0=RSA SRAM BIST test pass; 1=RSA SRAM BIST test fail
  [14] KSBRF — KS SRAM BIST Result Flag (Read Only). Note 1: This bit will be clear to 0 when KSBIST(SYS_SRAMBCTL[14]) set to 0.
    0=KS SRAM BIST test pass; 1=KS SRAM BIST test fail
  [13] I3CBRF — I3C SRAM BIST Result Flag (Read Only). Note 1: This bit will be clear to 0 when I3CBIST(SYS_SRAMBCTL[13]) set to 0.
    0=I3C SRAM BIST test pass; 1=I3C SRAM BIST test fail
  [12] CCAPBRF — CCAP SRAM BIST Result Flag (Read Only). Note 1: This bit will be clear to 0 when CCAPBIST(SYS_SRAMBCTL[12]) set to 0.
    0=CCAP SRAM BIST test pass; 1=CCAP SRAM BIST test fail
  [10] SPIM0BRF — SPIM0 SRAM BIST Result Flag (Read Only). Note 1: This bit will be clear to 0 when SPIM0BIST(SYS_SRAMBCTL[10]) set to 0.
    0=SPIM0 SRAM BIST test pass; 1=SPIM0 SRAM BIST test fail
  [9] CAN1BRF — CAN1 SRAM BIST Result Flag (Read Only). Note 1: This bit will be clear to 0 when CAN1BIST(SYS_SRAMBCTL[9]) set to 0.
    0=CAN1 SRAM BIST test pass; 1=CAN1 SRAM BIST test fail
  [8] CAN0BRF — CAN0 SRAM BIST Result Flag (Read Only). Note 1: This bit will be clear to 0 when CAN0BIST(SYS_SRAMBCTL[8]) set to 0.
    0=CAN0 SRAM BIST test pass; 1=CAN0 SRAM BIST test fail
  [4] LPSRBRF — Low Power System SRAM BIST Result Flag (Read Only). Note 1: This bit will be clear to 0 when LPSRBIST(SYS_SRAMBCTL[4]) set to 0.
    0=Low Power System SRAM BIST test pass; 1=Low Power System SRAM BIST test fail
  [3] SR3BRF — System SRAM 3 BIST Result Flag (Read Only). Note 1: This bit will be clear to 0 when SR3BIST(SYS_SRAMBCTL[3]) set to 0.
    0=System SRAM 3 BIST test pass; 1=System SRAM 3 BIST test fail
  [2] SR2BRF — System SRAM 2 BIST Result Flag (Read Only). Note 1: This bit will be clear to 0 when SR2BIST(SYS_SRAMBCTL[3]) set to 0.
    0=System SRAM 2 BIST test pass; 1=System SRAM 2 BIST test fail
  [1] SR1BRF — System SRAM 1 BIST Result Flag (Read Only). Note 1: This bit will be clear to 0 when SR1BIST(SYS_SRAMBCTL[1]) set to 0.
    0=System SRAM 1 BIST test pass; 1=System SRAM 1 BIST test fail
  [0] SR0BRF — System SRAM 0 BIST Result Flag (Read Only). Note 1: This bit will be clear to 0 when SR0BIST(SYS_SRAMBCTL[0]) set to 0.
    0=System SRAM 0 BIST test pass; 1=System SRAM 0 BIST test fail
